# CC27x0 register map
File version: 1.0
CPU: CM4 r0p4, little endian, no MPU, no FPU, VTOR, 3 interrupt priority bits
Registers are 32-bit, read-write, reset 0x0 unless marked. A register's access mark holds for its fields unless they carry their own. Offsets are from the block's base; [hi:lo] are bit positions; {n}, {i} and the like mark numbered series.

## LRFDTXF
Base 0x40081800
0x00 TXD — TX FIFO data. When written the register data is pushed to the TX FIFO. When read, data is popped from the TX FIFO
  [31:0] DATA — TX FIFO data. When written the register data is pushed to the TX FIFO. When read, data is popped from the TX FIFO. When writing or reading this register the access size will determine how many bytes are pushed to or popped from the FIFO. It is possible to push or pop 1,2 or 4 bytes depending on the access being done.

## DIB
Base 0xE000EFB0
0x00 DLAR — Provides CoreSight discovery information for the SCS
  [0] KEY ro — Indicates whether Non-secure invasive debug is allowed
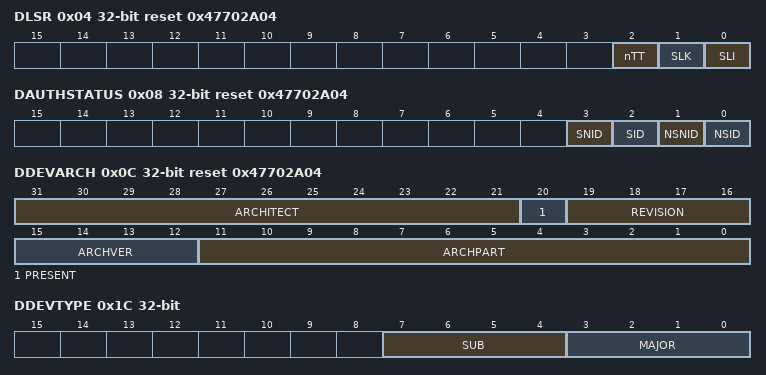
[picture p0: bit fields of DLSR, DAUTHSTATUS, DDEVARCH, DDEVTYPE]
0x04 DLSR reset 0x47702A04 — Provides CoreSight discovery information for the SCS
  [2] nTT ro — Indicates whether Secure invasive debug is implemented and allowed
  [1] SLK ro — Indicates whether Non-secure non-invasive debug is allowed
  [0] SLI ro — Indicates whether Non-secure invasive debug is allowed
0x08 DAUTHSTATUS reset 0x47702A04 — Provides CoreSight discovery information for the SCS
  [3] SNID ro — Indicates whether Secure non-invasive debug is implemented and allowed
  [2] SID ro — Indicates whether Secure invasive debug is implemented and allowed
  [1] NSNID ro — Indicates whether Non-secure non-invasive debug is allowed
  [0] NSID ro — Indicates whether Non-secure invasive debug is allowed
0x0C DDEVARCH reset 0x47702A04 — Provides CoreSight discovery information for the SCS
  [31:21] ARCHITECT ro — Defines the architect of the component. Bits [31:28] are the JEP106 continuation code (JEP106 bank ID, minus 1) and bits [27:21] are the JEP106 ID code.
  [20] PRESENT ro — Defines that the DEVARCH register is present
  [19:16] REVISION ro — Defines the architecture revision of the component
  [15:12] ARCHVER ro — Defines the architecture version of the component
  [11:0] ARCHPART ro — Defines the architecture of the component
0x1C DDEVTYPE — Provides CoreSight discovery information for the SCS
  [7:4] SUB ro — Component sub-type
  [3:0] MAJOR ro — CoreSight major type
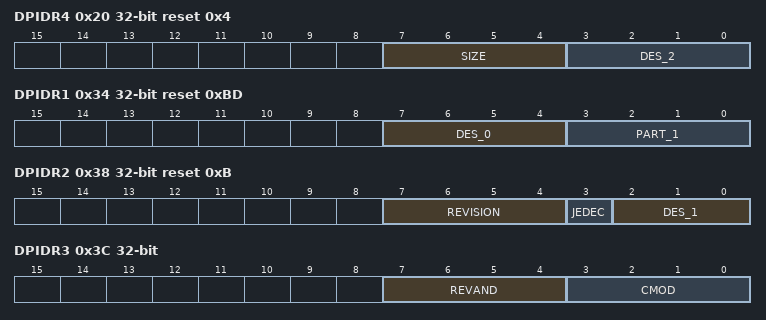
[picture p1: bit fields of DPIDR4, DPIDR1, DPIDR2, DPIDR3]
0x20 DPIDR4 reset 0x4 — Provides CoreSight discovery information for the SCS
  [7:4] SIZE ro — See CoreSight Architecture Specification
  [3:0] DES_2 ro — See CoreSight Architecture Specification
{0x10+4i} DPIDR{i} (i=5..7) — Provides CoreSight discovery information for the SCS
0x30 DPIDR0 reset 0x21 — Provides CoreSight discovery information for the SCS
  [7:0] PART_0 ro — See CoreSight Architecture Specification
0x34 DPIDR1 reset 0xBD — Provides CoreSight discovery information for the SCS
  [7:4] DES_0 ro — See CoreSight Architecture Specification
  [3:0] PART_1 ro — See CoreSight Architecture Specification
0x38 DPIDR2 reset 0xB — Provides CoreSight discovery information for the SCS
  [7:4] REVISION ro — See CoreSight Architecture Specification
  [3] JEDEC ro — See CoreSight Architecture Specification
  [2:0] DES_1 ro — See CoreSight Architecture Specification
0x3C DPIDR3 — Provides CoreSight discovery information for the SCS
  [7:4] REVAND ro — See CoreSight Architecture Specification
  [3:0] CMOD ro — See CoreSight Architecture Specification
0x40 DCIDR0 reset 0xD — Provides CoreSight discovery information for the SCS
  [7:0] PRMBL_0 ro — See CoreSight Architecture Specification
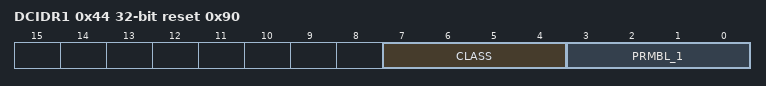
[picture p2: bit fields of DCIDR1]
0x44 DCIDR1 reset 0x90 — Provides CoreSight discovery information for the SCS
  [7:4] CLASS ro — See CoreSight Architecture Specification
  [3:0] PRMBL_1 ro — See CoreSight Architecture Specification
0x48 DCIDR2 reset 0x5 — Provides CoreSight discovery information for the SCS
  [7:0] PRMBL_2 ro — See CoreSight Architecture Specification
0x4C DCIDR3 reset 0xB1 — Provides CoreSight discovery information for the SCS
  [7:0] PRMBL_3 ro — See CoreSight Architecture Specification
